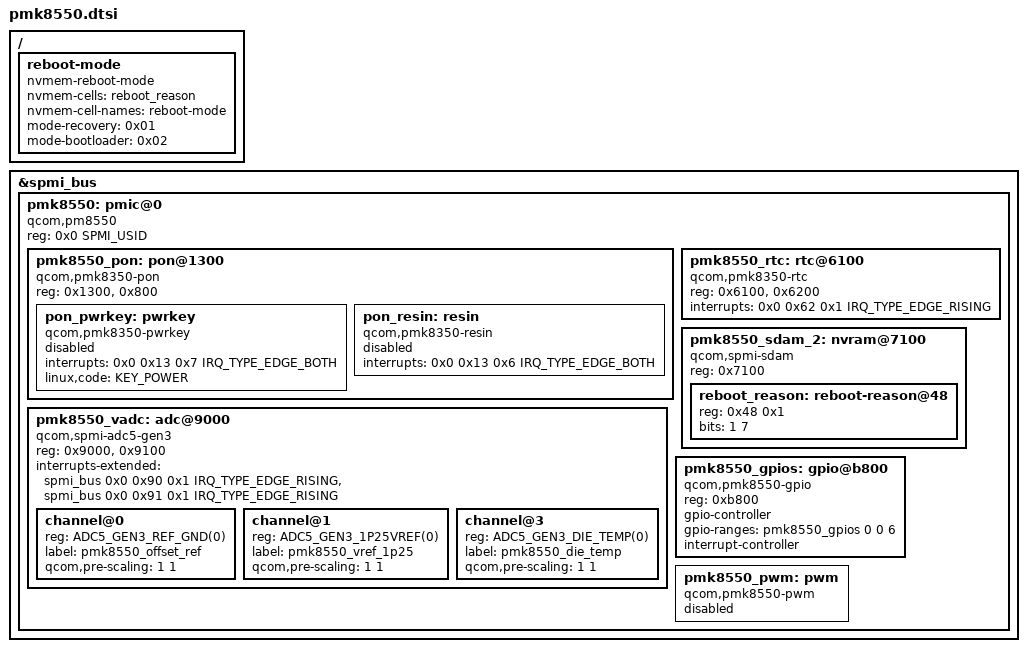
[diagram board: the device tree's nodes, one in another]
// SPDX-License-Identifier: BSD-3-Clause
/*
 * Copyright (c) 2022, Linaro Limited
 */

#include <dt-bindings/input/input.h>
#include <dt-bindings/input/linux-event-codes.h>
#include <dt-bindings/interrupt-controller/irq.h>
#include <dt-bindings/spmi/spmi.h>
#include "qcom-adc5-gen3.h"

/ {
	reboot-mode {
		compatible = "nvmem-reboot-mode";
		nvmem-cells = <&reboot_reason>;
		nvmem-cell-names = "reboot-mode";
		mode-recovery = <0x01>;
		mode-bootloader = <0x02>;
	};
};

&spmi_bus {
	pmk8550: pmic@0 {
		compatible = "qcom,pm8550", "qcom,spmi-pmic";
		reg = <0x0 SPMI_USID>;
		#address-cells = <1>;
		#size-cells = <0>;

		pmk8550_pon: pon@1300 {
			compatible = "qcom,pmk8350-pon";
			reg = <0x1300>, <0x800>;
			reg-names = "hlos", "pbs";

			pon_pwrkey: pwrkey {
				compatible = "qcom,pmk8350-pwrkey";
				interrupts = <0x0 0x13 0x7 IRQ_TYPE_EDGE_BOTH>;
				linux,code = <KEY_POWER>;
				status = "disabled";
			};

			pon_resin: resin {
				compatible = "qcom,pmk8350-resin";
				interrupts = <0x0 0x13 0x6 IRQ_TYPE_EDGE_BOTH>;
				status = "disabled";
			};
		};

		pmk8550_rtc: rtc@6100 {
			compatible = "qcom,pmk8350-rtc";
			reg = <0x6100>, <0x6200>;
			reg-names = "rtc", "alarm";
			interrupts = <0x0 0x62 0x1 IRQ_TYPE_EDGE_RISING>;
		};

		pmk8550_sdam_2: nvram@7100 {
			compatible = "qcom,spmi-sdam";
			reg = <0x7100>;
			#address-cells = <1>;
			#size-cells = <1>;
			ranges = <0 0x7100 0x100>;

			reboot_reason: reboot-reason@48 {
				reg = <0x48 0x1>;
				bits = <1 7>;
			};
		};

		pmk8550_vadc: adc@9000 {
			compatible = "qcom,spmi-adc5-gen3";
			reg = <0x9000>, <0x9100>;
			interrupts-extended = <&spmi_bus 0x0 0x90 0x1 IRQ_TYPE_EDGE_RISING>,
					      <&spmi_bus 0x0 0x91 0x1 IRQ_TYPE_EDGE_RISING>;
			#address-cells = <1>;
			#size-cells = <0>;
			#io-channel-cells = <1>;
			#thermal-sensor-cells = <1>;

			channel@0 {
				reg = <ADC5_GEN3_REF_GND(0)>;
				label = "pmk8550_offset_ref";
				qcom,pre-scaling = <1 1>;
			};

			channel@1 {
				reg = <ADC5_GEN3_1P25VREF(0)>;
				label = "pmk8550_vref_1p25";
				qcom,pre-scaling = <1 1>;
			};

			channel@3 {
				reg = <ADC5_GEN3_DIE_TEMP(0)>;
				label = "pmk8550_die_temp";
				qcom,pre-scaling = <1 1>;
			};
		};

		pmk8550_gpios: gpio@b800 {
			compatible = "qcom,pmk8550-gpio", "qcom,spmi-gpio";
			reg = <0xb800>;
			gpio-controller;
			gpio-ranges = <&pmk8550_gpios 0 0 6>;
			#gpio-cells = <2>;
			interrupt-controller;
			#interrupt-cells = <2>;
		};

		pmk8550_pwm: pwm {
			compatible = "qcom,pmk8550-pwm";

			#address-cells = <1>;
			#size-cells = <0>;
			#pwm-cells = <2>;

			status = "disabled";
		};
	};
};
